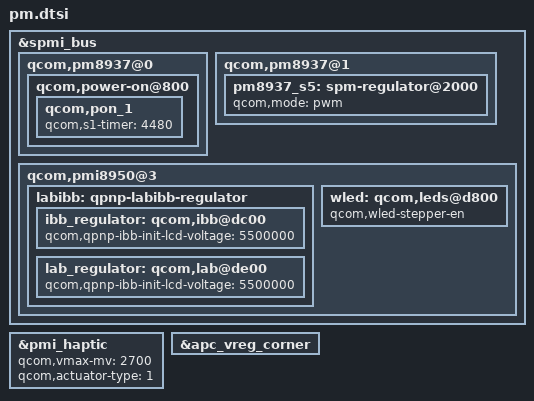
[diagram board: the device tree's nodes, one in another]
&spmi_bus {
	qcom,pm8937@0 {
		qcom,power-on@800 {
			qcom,pon_1 {
				qcom,s1-timer = <4480>;
			};
		};
	};

	qcom,pm8937@1 {
		pm8937_s5: spm-regulator@2000 {
			qcom,mode = "pwm";
		};
	};

	qcom,pmi8950@3 {
		labibb: qpnp-labibb-regulator {
			ibb_regulator: qcom,ibb@dc00 {
				/delete-property/
					qcom,qpnp-ibb-use-default-voltage;
				qcom,qpnp-ibb-init-lcd-voltage = <5500000>;
			};

			lab_regulator: qcom,lab@de00 {
				/delete-property/
					qcom,qpnp-ibb-use-default-voltage;
				qcom,qpnp-ibb-init-lcd-voltage = <5500000>;
			};
		};
		wled: qcom,leds@d800 {
			qcom,wled-stepper-en;
		};
	};
};

&pmi_haptic {
	/delete-property/ qcom,en-brake;
	qcom,vmax-mv = <2700>;
	qcom,actuator-type = <1>;
};

&apc_vreg_corner {
	/delete-property/ qcom,cpr-enable;
};
